# nrf54lm20b_application register map
Vendor: Nordic Semiconductor; Series: nrf54l; File version: 1
CPU: CM33 r0p4, little endian, MPU, FPU, 3 interrupt priority bits, 270 interrupts, 4 SAU regions
Registers are 32-bit, read-write, reset 0x0 unless marked. A register's access mark holds for its fields unless they carry their own. Offsets are from the block's base; [hi:lo] are bit positions; lines under a group give offsets from that group; 'fields as' and 'values as' point back to an identical list.

## GLOBAL_CTRLAP_NS — Control access port 0
Base 0x40052000
Same registers: GLOBAL_CTRLAP_S 0x50052000
0x100 EVENTS_RXREADY — RXSTATUS is changed to DataPending.
  [0] EVENTS_RXREADY
    0=NotGenerated (Event not generated); 1=Generated (Event generated)
0x104 EVENTS_TXDONE — TXSTATUS is changed to NoDataPending.
  [0] EVENTS_TXDONE
    values as EVENTS_RXREADY.EVENTS_RXREADY
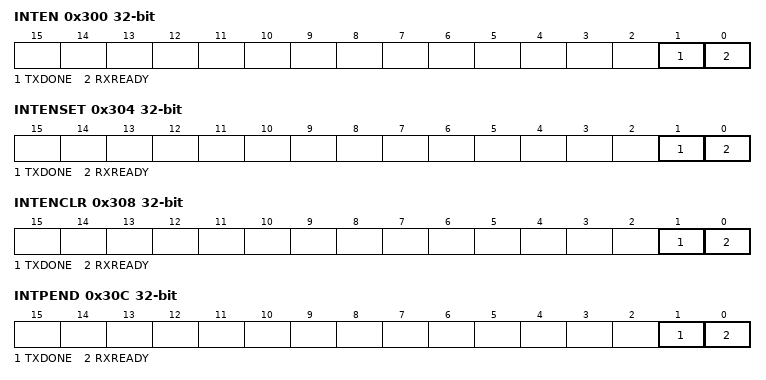
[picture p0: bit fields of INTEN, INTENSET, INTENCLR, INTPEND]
0x300 INTEN — Enable or disable interrupt
  [1] TXDONE — Enable or disable interrupt for event TXDONE
    0=Disabled; 1=Enabled
  [0] RXREADY — Enable or disable interrupt for event RXREADY
    0=Disabled; 1=Enabled
0x304 INTENSET — Enable interrupt
  [1] TXDONE write-1-sets — Write '1' to enable interrupt for event TXDONE
    on read: 0=Disabled (Read: Disabled); 1=Enabled (Read: Enabled) | on write: 1=Set (Enable)
  [0] RXREADY write-1-sets — Write '1' to enable interrupt for event RXREADY
    values as TXDONE
0x308 INTENCLR — Disable interrupt
  [1] TXDONE write-1-clears — Write '1' to disable interrupt for event TXDONE
    on read: 0=Disabled (Read: Disabled); 1=Enabled (Read: Enabled) | on write: 1=Clear (Disable)
  [0] RXREADY write-1-clears — Write '1' to disable interrupt for event RXREADY
    values as TXDONE
0x30C INTPEND ro — Pending interrupts
  [1] TXDONE — Read pending status of interrupt for event TXDONE
    on read: 0=NotPending (Read: Not pending); 1=Pending (Read: Pending)
  [0] RXREADY — Read pending status of interrupt for event RXREADY
    values as TXDONE
0x400 MAILBOX group — Unspecified
  0x00 RXDATA ro — Data sent from the debugger to the CPU.
    [31:0] RXDATA — Data received from debugger.
  0x04 RXSTATUS ro — Status to indicate if data sent from the debugger to the CPU has been read.
    [0] RXSTATUS — Status of data in register RXDATA.
      0=NoDataPending (No data is pending in register RXDATA.); 1=DataPending (Data is pending in register RXDATA.)
  0x80 TXDATA — Data sent from the CPU to the debugger.
    [31:0] TXDATA — Data sent to debugger.
  0x84 TXSTATUS ro — Status to indicate if data sent from the CPU to the debugger has been read.
    [0] TXSTATUS — Status of data in register TXDATA.
      0=NoDataPending (No data is pending in register TXDATA.); 1=DataPending (Data is pending in register TXDATA.)
0x500 ERASEPROTECT group — Unspecified
  0x00 LOCK rw-once — This register locks the ERASEPROTECT.DISABLE register from being written until next reset.
    [0] LOCK — Writing any value will lock the ERASEPROTECT.DISABLE register from being written until next reset.
      1=Locked (Register ERASEPROTECT.DISABLE is read-only.)
  0x04 DISABLE write-once — This register disables the ERASEPROTECT register and performs an ERASEALL operation.
    [31:0] KEY — The ERASEALL sequence is initiated if the value of the KEY fields are non-zero and the KEY fields match on both the CPU and debugger sides.
0x520 RESET wo — System reset request.
  [2:0] RESET — Reset request
    0=No reset is generated; 1=SoftReset (Perform a device soft reset); 2=HardReset (Perform a device hard reset); 4=PinReset (Perform a device pin reset)

## GLOBAL_TAD_NS — Trace and debug control 0
Base 0x40053000
Same registers: GLOBAL_TAD_S 0x50053000
0x400 SYSPWRUPREQ — System power-up request
  [0] ACTIVE — Activate power-up request
    0=NotActive (Power-up request not active); 1=Active (Power-up request active)
0x404 DBGPWRUPREQ — Debug power-up request
  fields as SYSPWRUPREQ
0x500 ENABLE — Enable debug domain and acquire selected GPIOs
  [0] ENABLE
    0=DISABLED (Disable debug domain and release selected GPIOs); 1=ENABLED (Enable debug domain and acquire selected GPIOs)
0x518 TRACEPORTSPEED
  [1:0] TRACEPORTSPEED — Trace port speed is divided from CPU clock. The TRACECLK pin output will be divided again by two from the trace port clock.
    0=DIV1 (Trace port speed equals CPU clock); 1=DIV2 (Trace port speed equals CPU clock divided by 2); 2=DIV4 (Trace port speed equals CPU clock divided by 4); 3=DIV32 (Trace port speed equals CPU clock divided by 32)
